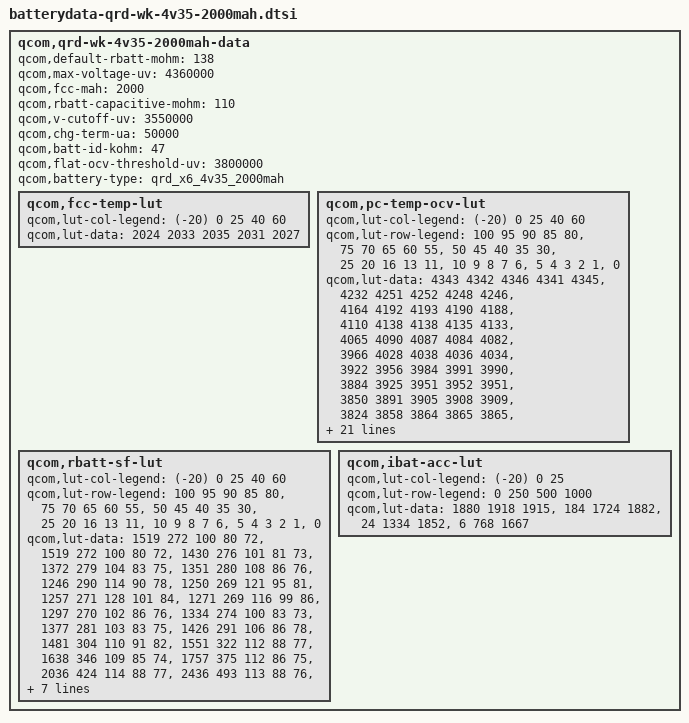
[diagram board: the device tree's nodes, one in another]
/* Copyright (c) 2014, The Linux Foundation. All rights reserved.
 *
 * This program is free software; you can redistribute it and/or modify
 * it under the terms of the GNU General Public License version 2 and
 * only version 2 as published by the Free Software Foundation.
 *
 * This program is distributed in the hope that it will be useful,
 * but WITHOUT ANY WARRANTY; without even the implied warranty of
 * MERCHANTABILITY or FITNESS FOR A PARTICULAR PURPOSE.  See the
 * GNU General Public License for more details.
 */

qcom,qrd-wk-4v35-2000mah-data {
	qcom,default-rbatt-mohm = <138>;
	qcom,max-voltage-uv = <4360000>;
	qcom,fcc-mah = <2000>;
	qcom,rbatt-capacitive-mohm = <110>;
	qcom,v-cutoff-uv = <3550000>;
	qcom,chg-term-ua = <50000>;
	qcom,batt-id-kohm = <47>;
	qcom,flat-ocv-threshold-uv = <3800000>;
	qcom,battery-type = "qrd_x6_4v35_2000mah";

	qcom,fcc-temp-lut {
		qcom,lut-col-legend = <(-20) 0 25 40 60>;
		qcom,lut-data = <2024 2033 2035 2031 2027>;
	};

	qcom,pc-temp-ocv-lut {
		qcom,lut-col-legend = <(-20) 0 25 40 60>;
		qcom,lut-row-legend = <100 95 90 85 80>,
				<75 70 65 60 55>,
				<50 45 40 35 30>,
				<25 20 16 13 11>,
				<10 9 8 7 6>,
				<5 4 3 2 1 >,
				<0>;
		qcom,lut-data = <4343 4342 4346 4341 4345>,
				<4232 4251 4252 4248 4246>,
				<4164 4192 4193 4190 4188>,
				<4110 4138 4138 4135 4133>,
				<4065 4090 4087 4084 4082>,
				<3966 4028 4038 4036 4034>,
				<3922 3956 3984 3991 3990>,
				<3884 3925 3951 3952 3951>,
				<3850 3891 3905 3908 3909>,
				<3824 3858 3864 3865 3865>,
				<3804 3830 3836 3836 3836>,
				<3786 3807 3814 3814 3813>,
				<3772 3788 3796 3796 3795>,
				<3757 3774 3781 3782 3780>,
				<3744 3763 3768 3764 3758>,
				<3728 3750 3754 3744 3732>,
				<3710 3730 3736 3727 3713>,
				<3691 3718 3718 3708 3694>,
				<3672 3710 3700 3690 3678>,
				<3654 3704 3690 3682 3670>,
				<3645 3700 3688 3680 3668>,
				<3634 3695 3687 3679 3667>,
				<3622 3689 3684 3676 3665>,
				<3604 3680 3679 3672 3659>,
				<3584 3663 3666 3658 3641>,
				<3558 3635 3634 3623 3608>,
				<3524 3595 3586 3576 3562>,
				<3478 3540 3526 3518 3504>,
				<3408 3461 3446 3440 3424>,
				<3284 3336 3331 3320 3302>,
				<3000 3000 3036 3012 3000>;
	};
	qcom,rbatt-sf-lut {
		qcom,lut-col-legend = <(-20) 0 25 40 60>;
		qcom,lut-row-legend = <100 95 90 85 80>,
				<75 70 65 60 55>,
				<50 45 40 35 30>,
				<25 20 16 13 11>,
				<10 9 8 7 6>,
				<5  4 3 2 1>,
				<0>;
		qcom,lut-data = <1519 272 100 80 72>,
				<1519 272 100 80 72>,
				<1430 276 101 81 73>,
				<1372 279 104 83 75>,
				<1351 280 108 86 76>,
				<1246 290 114 90 78>,
				<1250 269 121 95 81>,
				<1257 271 128 101 84>,
				<1271 269 116 99 86>,
				<1297 270 102 86 76>,
				<1334 274 100 83 73>,
				<1377 281 103 83 75>,
				<1426 291 106 86 78>,
				<1481 304 110 91 82>,
				<1551 322 112 88 77>,
				<1638 346 109 85 74>,
				<1757 375 112 86 75>,
				<2036 424 114 88 77>,
				<2436 493 113 88 76>,
				<2769 549 116 88 77>,
				<2915 575 118 91 80>,
				<2845 564 120 92 81>,
				<3206 596 123 94 83>,
				<3678 639 129 97 86>,
				<4309 693 131 96 82>,
				<5148 763 129 91 80>,
				<6335 868 136 95 81>,
				<8116 1028 147 100 86>,
				<10972 1271 167 113 92>,
				<18999 2193 213 132 107>,
				<37997 4386 426 264 213>;
	};
	qcom,ibat-acc-lut {
		qcom,lut-col-legend = <(-20) 0 25>;
		qcom,lut-row-legend = <0 250 500 1000>;
		qcom,lut-data = <1880 1918 1915>,
				<184 1724 1882>,
				<24 1334 1852>,
				<6 768 1667>;
	};
};
